AUTOSAR XML (schema 00044)
package /MICROSAR/EcuM_swc/ComponentTypes
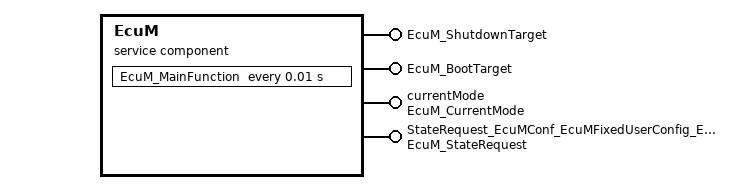
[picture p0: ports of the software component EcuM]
  service sw component type EcuM
    4 x provide port:
      EcuM_ShutdownTarget: provided-interface=EcuM_ShutdownTarget
        provided-com-specs:
          operation=SelectShutdownTarget, queue-length=1
          operation=GetShutdownTarget, queue-length=1
          operation=GetLastShutdownTarget, queue-length=1
          operation=SelectShutdownCause, queue-length=1
          operation=GetShutdownCause, queue-length=1
      EcuM_BootTarget: provided-com-specs=[{operation=SelectBootTarget, queue-length=1}, {operation=GetBootTarget, queue-length=1}], provided-interface=EcuM_BootTarget
      currentMode: mode-switch-sender-com-spec{mode-group=currentMode, mode-switched-ack=timeout=0, queue-length=1}, provided-interface=EcuM_CurrentMode
      StateRequest_EcuMConf_EcuMFixedUserConfig_EcuMUserConfig_CTRL_App: provided-interface=EcuM_StateRequest
        provided-com-specs:
          operation=ReleasePOSTRUN, queue-length=1
          operation=ReleaseRUN, queue-length=1
          operation=RequestPOSTRUN, queue-length=1
          operation=RequestRUN, queue-length=1
          operation=GetStateWrapper, queue-length=1
    behavior EcuMInternalBehavior: data-type-mapping=EcuMMode_DataTypeMappingSet, included-data-type-set=data-type=[EcuM_StateType, EcuM_ModeType, EcuM_TimeType, EcuM_UserType, EcuM_ShutdownCauseType, EcuM_BootTargetType]
      timing event Timer_EcuM_MainFunction: start-on-event=EcuM_MainFunction, period=0.01
      12 x operation invoked event:
        OpEventSelectShutdownTarget_SelectShutdownTarget_EcuM_ShutdownTarget: start-on-event=SelectShutdownTarget, operation=EcuM_ShutdownTarget.SelectShutdownTarget
        OpEventGetShutdownTarget_GetShutdownTarget_EcuM_ShutdownTarget: start-on-event=GetShutdownTarget, operation=EcuM_ShutdownTarget.GetShutdownTarget
        OpEventGetLastShutdownTarget_GetLastShutdownTarget_EcuM_ShutdownTarget: start-on-event=GetLastShutdownTarget, operation=EcuM_ShutdownTarget.GetLastShutdownTarget
        OpEventSelectShutdownCause_SelectShutdownCause_EcuM_ShutdownTarget: start-on-event=SelectShutdownCause, operation=EcuM_ShutdownTarget.SelectShutdownCause
        OpEventGetShutdownCause_GetShutdownCause_EcuM_ShutdownTarget: start-on-event=GetShutdownCause, operation=EcuM_ShutdownTarget.GetShutdownCause
        OpEventSelectBootTarget_SelectBootTarget_EcuM_BootTarget: start-on-event=SelectBootTarget, operation=EcuM_BootTarget.SelectBootTarget
        OpEventGetBootTarget_GetBootTarget_EcuM_BootTarget: start-on-event=GetBootTarget, operation=EcuM_BootTarget.GetBootTarget
        OpEventReleasePOSTRUN_ReleasePOSTRUN_StateRequest_EcuMConf_EcuMFixedUserConfig_EcuMUserConfig_CTRL_App: start-on-event=ReleasePOSTRUN, operation=StateRequest_EcuMConf_EcuMFixedUserConfig_EcuMUserConfig_CTRL_App.ReleasePOSTRUN
        OpEventReleaseRUN_ReleaseRUN_StateRequest_EcuMConf_EcuMFixedUserConfig_EcuMUserConfig_CTRL_App: start-on-event=ReleaseRUN, operation=StateRequest_EcuMConf_EcuMFixedUserConfig_EcuMUserConfig_CTRL_App.ReleaseRUN
        OpEventRequestPOSTRUN_RequestPOSTRUN_StateRequest_EcuMConf_EcuMFixedUserConfig_EcuMUserConfig_CTRL_App: start-on-event=RequestPOSTRUN, operation=StateRequest_EcuMConf_EcuMFixedUserConfig_EcuMUserConfig_CTRL_App.RequestPOSTRUN
        OpEventRequestRUN_RequestRUN_StateRequest_EcuMConf_EcuMFixedUserConfig_EcuMUserConfig_CTRL_App: start-on-event=RequestRUN, operation=StateRequest_EcuMConf_EcuMFixedUserConfig_EcuMUserConfig_CTRL_App.RequestRUN
        OpEventGetStateWrapper_GetStateWrapper_StateRequest_EcuMConf_EcuMFixedUserConfig_EcuMUserConfig_CTRL_App: start-on-event=GetStateWrapper, operation=StateRequest_EcuMConf_EcuMFixedUserConfig_EcuMUserConfig_CTRL_App.GetStateWrapper
      port-api-options:
        enable-take-address=true, indirect-api=false, port=currentMode
        enable-take-address=true, indirect-api=false, port=EcuM_ShutdownTarget
        enable-take-address=true, indirect-api=false, port=EcuM_BootTarget
        {enable-take-address=true, indirect-api=false, port-defined-argument-value{value=user:0, value-type=EcuM_UserType}, port=StateRequest_EcuMConf_EcuMFixedUserConfig_EcuMUserConfig_CTRL_App}
      13 x runnable:
        EcuM_MainFunction
          mode switch point ModeSwitchPointEcuM_MainFunction_currentMode_currentMode: mode-group=currentMode.currentMode
        SelectShutdownTarget: can-be-invoked-concurrently=true, symbol=EcuM_SelectShutdownTarget
        GetShutdownTarget: can-be-invoked-concurrently=true, symbol=EcuM_GetShutdownTarget
        GetLastShutdownTarget: can-be-invoked-concurrently=true, symbol=EcuM_GetLastShutdownTarget
        SelectShutdownCause: can-be-invoked-concurrently=true, symbol=EcuM_SelectShutdownCause
        GetShutdownCause: can-be-invoked-concurrently=true, symbol=EcuM_GetShutdownCause
        SelectBootTarget: can-be-invoked-concurrently=true, symbol=EcuM_SelectBootTarget
        GetBootTarget: can-be-invoked-concurrently=true, symbol=EcuM_GetBootTarget
        ReleasePOSTRUN: can-be-invoked-concurrently=true, symbol=EcuM_ReleasePOST_RUN
        ReleaseRUN: can-be-invoked-concurrently=true, symbol=EcuM_ReleaseRUN
        RequestPOSTRUN: can-be-invoked-concurrently=true, symbol=EcuM_RequestPOST_RUN
        RequestRUN: can-be-invoked-concurrently=true, symbol=EcuM_RequestRUN
        GetStateWrapper: can-be-invoked-concurrently=true, symbol=EcuM_GetStateWrapper
  swc implementation EcuMImplementation: behavior=EcuMInternalBehavior
